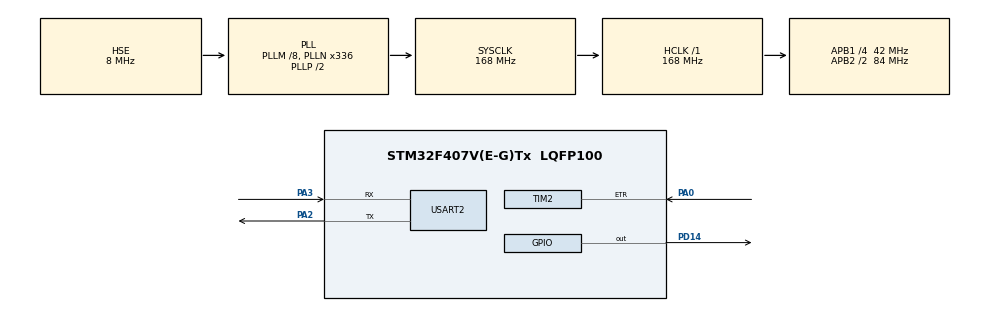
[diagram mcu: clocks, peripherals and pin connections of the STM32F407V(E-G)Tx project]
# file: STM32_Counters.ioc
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Mcu.Family=STM32F4
Mcu.Name=STM32F407V(E-G)Tx
Mcu.Package=LQFP100
NVIC.PriorityGroup=NVIC_PRIORITYGROUP_0
NVIC.TIM2_IRQn=true\:0\:0\:false\:false\:true\:true\:true\:true
PA0-WKUP.Signal=S_TIM2_CH1_ETR
PA13.Mode=Serial_Wire
PA13.Signal=SYS_JTMS-SWDIO
PA14.Mode=Serial_Wire
PA14.Signal=SYS_JTCK-SWCLK
PA2.Mode=Asynchronous
PA2.Signal=USART2_TX
PA3.Mode=Asynchronous
PA3.Signal=USART2_RX
PD14.Signal=GPIO_Output
PH0-OSC_IN.Mode=HSE-External-Oscillator
PH0-OSC_IN.Signal=RCC_OSC_IN
PH1-OSC_OUT.Mode=HSE-External-Oscillator
PH1-OSC_OUT.Signal=RCC_OSC_OUT
ProjectManager.HeapSize=0x200
ProjectManager.StackSize=0x400
ProjectManager.TargetToolchain=STM32CubeIDE
RCC.48MHZClocksFreq_Value=48000000
RCC.AHBFreq_Value=168000000
RCC.APB1CLKDivider=RCC_HCLK_DIV4
RCC.APB1Freq_Value=42000000
RCC.APB1TimFreq_Value=84000000
RCC.APB2CLKDivider=RCC_HCLK_DIV2
RCC.APB2Freq_Value=84000000
RCC.APB2TimFreq_Value=168000000
RCC.CortexFreq_Value=168000000
RCC.HCLKFreq_Value=168000000
RCC.HSE_VALUE=8000000
RCC.HSI_VALUE=16000000
RCC.PLLM=8
RCC.PLLN=336
RCC.PLLQ=7
RCC.PLLSourceVirtual=RCC_PLLSOURCE_HSE
RCC.SYSCLKFreq_VALUE=168000000
RCC.SYSCLKSource=RCC_SYSCLKSOURCE_PLLCLK
RCC.VCOOutputFreq_Value=336000000
SH.S_TIM2_CH1_ETR.0=TIM2_ETR,ClockSourceETR_Mode2
TIM2.AutoReloadPreload=TIM_AUTORELOAD_PRELOAD_ENABLE
TIM2.ClockFilter=15
TIM2.Period=20
USART2.VirtualMode=VM_ASYNC
board=STM32F407G-DISC1

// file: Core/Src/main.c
/* USER CODE BEGIN Header */
/**
  ******************************************************************************
  * @file           : main.c
  * @brief          : Main program body
  ******************************************************************************
  * @attention
  *
  * Copyright (c) 2026 STMicroelectronics.
  * All rights reserved.
  *
  * This software is licensed under terms that can be found in the LICENSE file
  * in the root directory of this software component.
  * If no LICENSE file comes with this software, it is provided AS-IS.
  *
  ******************************************************************************
  */
/* USER CODE END Header */
#include "main.h"

/* USER CODE BEGIN Includes */
#include<stdio.h>
#include<string.h>

/* USER CODE END Includes */

TIM_HandleTypeDef htim2;

UART_HandleTypeDef huart2;

void SystemClock_Config(void);
static void MX_GPIO_Init(void);
static void MX_TIM2_Init(void);
static void MX_USART2_UART_Init(void);

/* USER CODE BEGIN 0 */
char END_MSG[40]= "Overflow reached. Reset the counter\r\n";
void HAL_TIM_PeriodElapsedCallback(TIM_HandleTypeDef* htim){
	HAL_UART_Transmit(&huart2, (uint8_t*)END_MSG, strlen(END_MSG), 100);
}

/* USER CODE END 0 */

int main(void)
{

  /* MCU Configuration--------------------------------------------------------*/

  /* Reset of all peripherals, Initializes the Flash interface and the Systick. */
  HAL_Init();

  /* Configure the system clock */
  SystemClock_Config();

  /* Initialize all configured peripherals */
  MX_GPIO_Init();
  MX_TIM2_Init();
  MX_USART2_UART_Init();
  /* USER CODE BEGIN 2 */
HAL_TIM_Base_Start_IT(&htim2);
char MSG[20];
uint16_t CounterTicks = 0;
  /* USER CODE END 2 */

  /* Infinite loop */
  while (1)
  {

    /* USER CODE BEGIN 3 */
	  CounterTicks = TIM2->CNT;
	  sprintf(MSG, "TIcks %d\r\n", CounterTicks);
	  HAL_UART_Transmit(&huart2,(uint8_t*)MSG, strlen(MSG), 100);
	  HAL_Delay(100);
  }
  /* USER CODE END 3 */
}

void SystemClock_Config(void)
{
  RCC_OscInitTypeDef RCC_OscInitStruct = {0};
  RCC_ClkInitTypeDef RCC_ClkInitStruct = {0};

  /** Configure the main internal regulator output voltage
  */
  __HAL_RCC_PWR_CLK_ENABLE();
  __HAL_PWR_VOLTAGESCALING_CONFIG(PWR_REGULATOR_VOLTAGE_SCALE1);

  /** Initializes the RCC Oscillators according to the specified parameters
  * in the RCC_OscInitTypeDef structure.
  */
  RCC_OscInitStruct.OscillatorType = RCC_OSCILLATORTYPE_HSE;
  RCC_OscInitStruct.HSEState = RCC_HSE_ON;
  RCC_OscInitStruct.PLL.PLLState = RCC_PLL_ON;
  RCC_OscInitStruct.PLL.PLLSource = RCC_PLLSOURCE_HSE;
  RCC_OscInitStruct.PLL.PLLM = 8;
  RCC_OscInitStruct.PLL.PLLN = 336;
  RCC_OscInitStruct.PLL.PLLP = RCC_PLLP_DIV2;
  RCC_OscInitStruct.PLL.PLLQ = 7;
  if (HAL_RCC_OscConfig(&RCC_OscInitStruct) != HAL_OK)
  {
    Error_Handler();
  }

  /** Initializes the CPU, AHB and APB buses clocks
  */
  RCC_ClkInitStruct.ClockType = RCC_CLOCKTYPE_HCLK|RCC_CLOCKTYPE_SYSCLK
                              |RCC_CLOCKTYPE_PCLK1|RCC_CLOCKTYPE_PCLK2;
  RCC_ClkInitStruct.SYSCLKSource = RCC_SYSCLKSOURCE_PLLCLK;
  RCC_ClkInitStruct.AHBCLKDivider = RCC_SYSCLK_DIV1;
  RCC_ClkInitStruct.APB1CLKDivider = RCC_HCLK_DIV4;
  RCC_ClkInitStruct.APB2CLKDivider = RCC_HCLK_DIV2;

  if (HAL_RCC_ClockConfig(&RCC_ClkInitStruct, FLASH_LATENCY_5) != HAL_OK)
  {
    Error_Handler();
  }
}

static void MX_TIM2_Init(void)
{

  TIM_ClockConfigTypeDef sClockSourceConfig = {0};
  TIM_MasterConfigTypeDef sMasterConfig = {0};

  htim2.Instance = TIM2;
  htim2.Init.Prescaler = 0;
  htim2.Init.CounterMode = TIM_COUNTERMODE_UP;
  htim2.Init.Period = 20;
  htim2.Init.ClockDivision = TIM_CLOCKDIVISION_DIV1;
  htim2.Init.AutoReloadPreload = TIM_AUTORELOAD_PRELOAD_ENABLE;
  if (HAL_TIM_Base_Init(&htim2) != HAL_OK)
  {
    Error_Handler();
  }
  sClockSourceConfig.ClockSource = TIM_CLOCKSOURCE_ETRMODE2;
  sClockSourceConfig.ClockPolarity = TIM_CLOCKPOLARITY_NONINVERTED;
  sClockSourceConfig.ClockPrescaler = TIM_CLOCKPRESCALER_DIV1;
  sClockSourceConfig.ClockFilter = 15;
  if (HAL_TIM_ConfigClockSource(&htim2, &sClockSourceConfig) != HAL_OK)
  {
    Error_Handler();
  }
  sMasterConfig.MasterOutputTrigger = TIM_TRGO_RESET;
  sMasterConfig.MasterSlaveMode = TIM_MASTERSLAVEMODE_DISABLE;
  if (HAL_TIMEx_MasterConfigSynchronization(&htim2, &sMasterConfig) != HAL_OK)
  {
    Error_Handler();
  }

}

static void MX_USART2_UART_Init(void)
{

  huart2.Instance = USART2;
  huart2.Init.BaudRate = 115200;
  huart2.Init.WordLength = UART_WORDLENGTH_8B;
  huart2.Init.StopBits = UART_STOPBITS_1;
  huart2.Init.Parity = UART_PARITY_NONE;
  huart2.Init.Mode = UART_MODE_TX_RX;
  huart2.Init.HwFlowCtl = UART_HWCONTROL_NONE;
  huart2.Init.OverSampling = UART_OVERSAMPLING_16;
  if (HAL_UART_Init(&huart2) != HAL_OK)
  {
    Error_Handler();
  }

}

static void MX_GPIO_Init(void)
{
  GPIO_InitTypeDef GPIO_InitStruct = {0};

  /* GPIO Ports Clock Enable */
  __HAL_RCC_GPIOH_CLK_ENABLE();
  __HAL_RCC_GPIOA_CLK_ENABLE();
  __HAL_RCC_GPIOD_CLK_ENABLE();

  /*Configure GPIO pin Output Level */
  HAL_GPIO_WritePin(GPIOD, GPIO_PIN_14, GPIO_PIN_RESET);

  /*Configure GPIO pin : PD14 */
  GPIO_InitStruct.Pin = GPIO_PIN_14;
  GPIO_InitStruct.Mode = GPIO_MODE_OUTPUT_PP;
  GPIO_InitStruct.Pull = GPIO_NOPULL;
  GPIO_InitStruct.Speed = GPIO_SPEED_FREQ_LOW;
  HAL_GPIO_Init(GPIOD, &GPIO_InitStruct);

}

void Error_Handler(void)
{
  __disable_irq();
  while (1)
  {
  }
}
